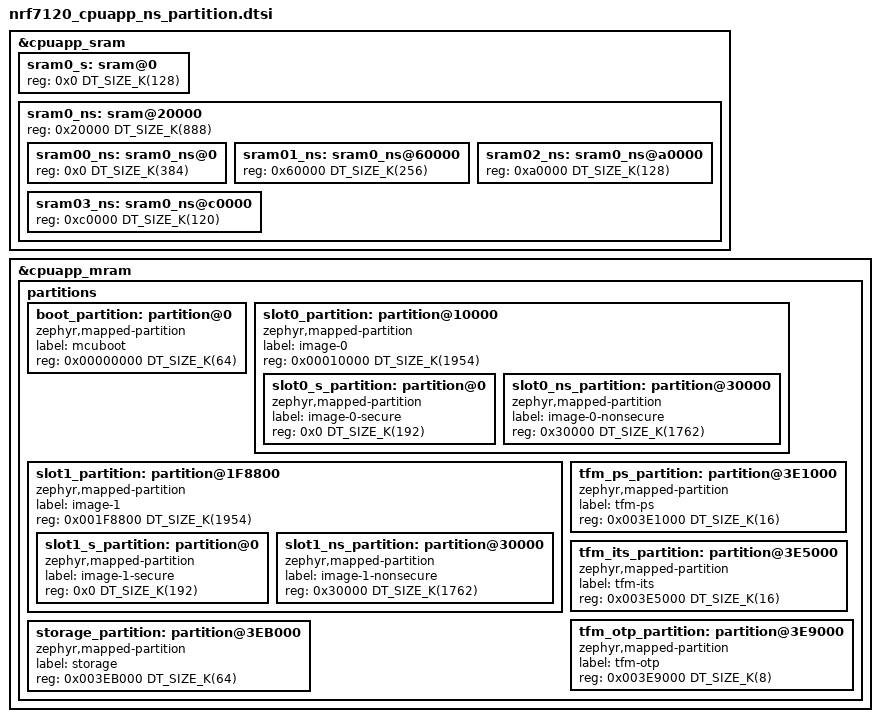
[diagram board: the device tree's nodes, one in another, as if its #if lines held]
/*
 * Copyright (c) 2025 Nordic Semiconductor ASA
 *
 * SPDX-License-Identifier: Apache-2.0
 *
 * Default memory partitioning for nRF7120 application CPU.
 */

/*
 * Default SRAM planning when building for nRF7120 with ARM TrustZone-M support
 * - Lowest 128 kB in RAM00 allocated to Secure RAM (sram0_s).
 * - Upper 384 kB in RAM00 allocated to Non-Secure RAM (sram00_ns).
 * - 256 kB SRAM in RAM01 allocated to Non-Secure RAM (sram01_ns).
 * - 128 kB SRAM in RAM02 allocated to Non-Secure RAM (sram02_ns).
 * - 120 kB SRAM in RAM03 allocated to Non-Secure RAM (sram03_ns).
 *
 * cpuapp_sram has 1016 kB of volatile memory (SRAM).
 * This static layout needs to be the same with the upstream TF-M layout in the
 * header flash_layout.h of the relevant platform. Any updates in the layout
 * needs to happen both in the flash_layout.h and in this file at the same time.
 */
&cpuapp_sram {
	sram0_s: sram@0 {
		#address-cells = <1>;
		#size-cells = <1>;
		/* Secure RAM */
		reg = <0x0 DT_SIZE_K(128)>; /* 0x2000_0000 */
		ranges = <0x0 0x0 DT_SIZE_K(128)>;
	};

	sram0_ns: sram@20000 {
		#address-cells = <1>;
		#size-cells = <1>;
		/* Non-Secure RAM */
		reg = <0x20000 DT_SIZE_K(888)>; /* 0x2002_0000 */
		ranges = <0x0 0x20000 DT_SIZE_K(888)>;

		sram00_ns: sram0_ns@0 {
			#address-cells = <1>;
			#size-cells = <1>;
			/* Non-Secure RAM */
			reg = <0x0 DT_SIZE_K(384)>; /* 0x2002_0000 */
			ranges = <0x0 0x0 DT_SIZE_K(384)>;
		};

		sram01_ns: sram0_ns@60000 {
			#address-cells = <1>;
			#size-cells = <1>;
			/* Non-Secure RAM */
			reg = <0x60000 DT_SIZE_K(256)>; /* 0x2008_0000 */
			ranges = <0x0 0x60000 DT_SIZE_K(256)>;
		};

		sram02_ns: sram0_ns@a0000 {
			#address-cells = <1>;
			#size-cells = <1>;
			/* Non-Secure RAM */
			reg = <0xa0000 DT_SIZE_K(128)>; /* 0x200C_0000 */
			ranges = <0x0 0xa0000 DT_SIZE_K(128)>;
		};

		sram03_ns: sram0_ns@c0000 {
			#address-cells = <1>;
			#size-cells = <1>;
			/* Non-Secure RAM */
			reg = <0xc0000 DT_SIZE_K(120)>; /* 0x200E_0000 */
			ranges = <0x0 0xc0000 DT_SIZE_K(120)>;
		};
	};
};

&cpuapp_mram {
	/*
	 * Default NVM layout on NRF7120 Application MCU without BL2:
	 * This layout matches (by necessity) that in the TF-M repository:
	 *
	 * 0x0000_0000 Boot Partition (64 KB)
	 *
	 * 0x0001_0000 Secure image primary (192 KB)
     * 0x0004_0000 Non-secure image primary (1762 KB)
     *
     * 0x001E_8800 Secure image secondary (192 KB)
     * 0x0021_8800 Non-secure image secondary (1762 KB)
     *
	 * 0x003C_1000 Protected Storage Area (16 KB)
	 * 0x003C_5000 Internal Trusted Storage Area (16 KB)
	 * 0x003C_9000 OTP / NV counters area (8 KB)
     *
	 * 0x003E_B000 Non-secure storage, used when built with NRF_NS_STORAGE=ON,
	 *             otherwise unused (64 KB)
	 */
#ifdef WITH_MCUBOOT_PARTITIONS
	partitions {
		#address-cells = <1>;
		#size-cells = <1>;
		ranges;

		/* This static layout needs to be the same with the upstream TF-M layout in the
		 * header flash_layout.h of the relevant platform. Any updates in the layout
		 * needs to happen both in the flash_layout.h and in this file at the same time.
		 */

		boot_partition: partition@0 {
			compatible = "zephyr,mapped-partition";
			label = "mcuboot";
			reg = <0x00000000 DT_SIZE_K(64)>;
		};

		slot0_partition: partition@10000 {
			compatible = "zephyr,mapped-partition";
			label = "image-0";
			reg = <0x00010000 DT_SIZE_K(1954)>;
			ranges = <0x0 0x00010000 DT_SIZE_K(1954)>;
			#address-cells = <1>;
			#size-cells = <1>;

			slot0_s_partition: partition@0 {
				compatible = "zephyr,mapped-partition";
				label = "image-0-secure";
				reg = <0x0 DT_SIZE_K(192)>;
			};

			slot0_ns_partition: partition@30000 {
				compatible = "zephyr,mapped-partition";
				label = "image-0-nonsecure";
				reg = <0x30000 DT_SIZE_K(1762)>;
			};
		};

		slot1_partition: partition@1F8800 {
			compatible = "zephyr,mapped-partition";
			label = "image-1";
			reg = <0x001F8800 DT_SIZE_K(1954)>;
			ranges = <0x0 0x001F8800 DT_SIZE_K(1954)>;
			#address-cells = <1>;
			#size-cells = <1>;

			slot1_s_partition: partition@0 {
				compatible = "zephyr,mapped-partition";
				label = "image-1-secure";
				reg = <0x0 DT_SIZE_K(192)>;
			};

			slot1_ns_partition: partition@30000 {
				compatible = "zephyr,mapped-partition";
				label = "image-1-nonsecure";
				reg = <0x30000 DT_SIZE_K(1762)>;
			};
		};

		tfm_ps_partition: partition@3E1000 {
			compatible = "zephyr,mapped-partition";
			label = "tfm-ps";
			reg = <0x003E1000 DT_SIZE_K(16)>;
		};

		tfm_its_partition: partition@3E5000 {
			compatible = "zephyr,mapped-partition";
			label = "tfm-its";
			reg = <0x003E5000 DT_SIZE_K(16)>;
		};

		tfm_otp_partition: partition@3E9000 {
			compatible = "zephyr,mapped-partition";
			label = "tfm-otp";
			reg = <0x003E9000 DT_SIZE_K(8)>;
		};

		storage_partition: partition@3EB000 {
			compatible = "zephyr,mapped-partition";
			label = "storage";
			reg = <0x003EB000 DT_SIZE_K(64)>;
		};
	};
#else
	/*
	 * Default NVM layout on NRF7120 Application MCU without BL2:
	 * This layout matches (by necessity) that in the TF-M repository:
	 *
	 * 0x0000_0000 Secure image primary (192 KB)
	 * 0x0003_0000 Protected Storage Area (16 KB)
	 * 0x0003_4000 Internal Trusted Storage Area (16 KB)
	 * 0x0003_8000 OTP / NV counters area (8 KB)
	 * 0x0003_A000 Non-secure image primary (3780 KB)
	 * 0x003E_B000 Non-secure storage, used when built with NRF_NS_STORAGE=ON,
	 *             otherwise unused (64 KB)
	 */
	partitions {
		#address-cells = <1>;
		#size-cells = <1>;
		ranges;

		/* This static layout needs to be the same with the upstream TF-M layout in the
		 * header flash_layout.h of the relevant platform. Any updates in the layout
		 * needs to happen both in the flash_layout.h and in this file at the same time.
		 */

		slot0_partition: partition@0 {
			compatible = "zephyr,mapped-partition";
			label = "image-0";
			reg = <0x0000000 DT_SIZE_K(192)>;
		};

		tfm_ps_partition: partition@30000 {
			compatible = "zephyr,mapped-partition";
			label = "tfm-ps";
			reg = <0x00030000 DT_SIZE_K(16)>;
		};

		tfm_its_partition: partition@34000 {
			compatible = "zephyr,mapped-partition";
			label = "tfm-its";
			reg = <0x00034000 DT_SIZE_K(16)>;
		};

		tfm_otp_partition: partition@38000 {
			compatible = "zephyr,mapped-partition";
			label = "tfm-otp";
			reg = <0x00038000 DT_SIZE_K(8)>;
		};

		slot0_ns_partition: partition@3a000 {
			compatible = "zephyr,mapped-partition";
			label = "image-0-nonsecure";
			reg = <0x0003a000 DT_SIZE_K(3780)>;
		};

		storage_partition: partition@3EB000 {
			compatible = "zephyr,mapped-partition";
			label = "storage";
			reg = <0x0003EB000 DT_SIZE_K(64)>;
		};
	};
#endif /* WITH_MCUBOOT_PARTITIONS */
};
